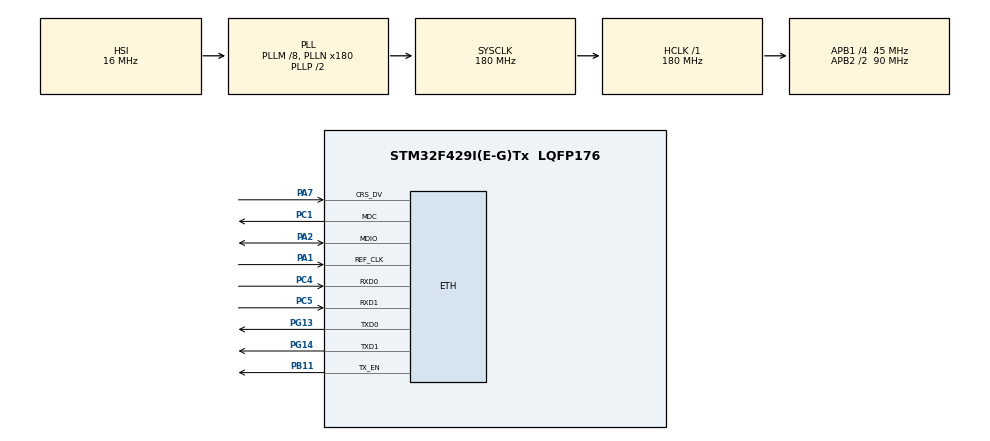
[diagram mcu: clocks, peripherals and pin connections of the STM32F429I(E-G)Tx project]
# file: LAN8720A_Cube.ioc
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ETH.MediaInterface=HAL_ETH_RMII_MODE
LWIP.BSP.number=1
LWIP.GATEWAY_ADDRESS=192.168.001.001
LWIP.IP_ADDRESS=192.168.001.100
LWIP.LWIP_ICMP=1
LWIP.LWIP_UDP=0
LWIP.NETMASK_ADDRESS=255.255.255.000
LWIP.Version=v2.1.2_Cube
LWIP0.BSP.STBoard=false
LWIP0.BSP.api=BSP_COMPONENT_DRIVER
LWIP0.BSP.component=LAN8742
LWIP0.BSP.instance=LAN8742
LWIP0.BSP.name=Driver_PHY
LWIP0.BSP.semaphore=S_LAN8742
LWIP0.BSP.solution=LAN8742
Mcu.Family=STM32F4
Mcu.Name=STM32F429I(E-G)Tx
Mcu.Package=LQFP176
NVIC.PriorityGroup=NVIC_PRIORITYGROUP_4
PA1.Mode=RMII
PA1.Signal=ETH_REF_CLK
PA2.Mode=RMII
PA2.Signal=ETH_MDIO
PA7.Mode=RMII
PA7.Signal=ETH_CRS_DV
PB11.Mode=RMII
PB11.Signal=ETH_TX_EN
PC1.Mode=RMII
PC1.Signal=ETH_MDC
PC4.Mode=RMII
PC4.Signal=ETH_RXD0
PC5.Mode=RMII
PC5.Signal=ETH_RXD1
PG13.Mode=RMII
PG13.Signal=ETH_TXD0
PG14.Mode=RMII
PG14.Signal=ETH_TXD1
ProjectManager.HeapSize=0x200
ProjectManager.StackSize=0x400
ProjectManager.TargetToolchain=MDK-ARM V5.32
RCC.48MHZClocksFreq_Value=90000000
RCC.AHBFreq_Value=180000000
RCC.APB1CLKDivider=RCC_HCLK_DIV4
RCC.APB1Freq_Value=45000000
RCC.APB1TimFreq_Value=90000000
RCC.APB2CLKDivider=RCC_HCLK_DIV2
RCC.APB2Freq_Value=90000000
RCC.APB2TimFreq_Value=180000000
RCC.CortexFreq_Value=180000000
RCC.HCLKFreq_Value=180000000
RCC.HSE_VALUE=25000000
RCC.HSI_VALUE=16000000
RCC.LSE_VALUE=32768
RCC.PLLM=8
RCC.PLLN=180
RCC.SYSCLKFreq_VALUE=180000000
RCC.SYSCLKSource=RCC_SYSCLKSOURCE_PLLCLK
RCC.VCOOutputFreq_Value=360000000
VP_LWIP_VS_Enabled.Mode=Enabled
board=custom

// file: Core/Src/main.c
/* USER CODE BEGIN Header */
/**
  ******************************************************************************
  * @file           : main.c
  * @brief          : Main program body
  ******************************************************************************
  * @attention
  *
  * Copyright (c) 2025 STMicroelectronics.
  * All rights reserved.
  *
  * This software is licensed under terms that can be found in the LICENSE file
  * in the root directory of this software component.
  * If no LICENSE file comes with this software, it is provided AS-IS.
  *
  ******************************************************************************
  */
/* USER CODE END Header */
#include "main.h"
#include "lwip.h"
#include "gpio.h"

/* USER CODE BEGIN Includes */
#include "tcpclient.h"
#include "tcpserver.h"
/* USER CODE END Includes */

void SystemClock_Config(void);

int main(void)
{

  /* MCU Configuration--------------------------------------------------------*/

  /* Reset of all peripherals, Initializes the Flash interface and the Systick. */
  HAL_Init();

  /* Configure the system clock */
  SystemClock_Config();

  /* Initialize all configured peripherals */
  MX_GPIO_Init();
  MX_LWIP_Init();
  /* USER CODE BEGIN 2 */
	TCP_Client_Init();
	TCP_Echo_Init();
  /* USER CODE END 2 */

  /* Infinite loop */
  /* USER CODE BEGIN WHILE */
  while (1)
  {
		MX_LWIP_Process();
    /* USER CODE END WHILE */

  }
}

void SystemClock_Config(void)
{
  RCC_OscInitTypeDef RCC_OscInitStruct = {0};
  RCC_ClkInitTypeDef RCC_ClkInitStruct = {0};

  /** Configure the main internal regulator output voltage
  */
  __HAL_RCC_PWR_CLK_ENABLE();
  __HAL_PWR_VOLTAGESCALING_CONFIG(PWR_REGULATOR_VOLTAGE_SCALE1);

  /** Initializes the RCC Oscillators according to the specified parameters
  * in the RCC_OscInitTypeDef structure.
  */
  RCC_OscInitStruct.OscillatorType = RCC_OSCILLATORTYPE_HSI;
  RCC_OscInitStruct.HSIState = RCC_HSI_ON;
  RCC_OscInitStruct.HSICalibrationValue = RCC_HSICALIBRATION_DEFAULT;
  RCC_OscInitStruct.PLL.PLLState = RCC_PLL_ON;
  RCC_OscInitStruct.PLL.PLLSource = RCC_PLLSOURCE_HSI;
  RCC_OscInitStruct.PLL.PLLM = 8;
  RCC_OscInitStruct.PLL.PLLN = 180;
  RCC_OscInitStruct.PLL.PLLP = RCC_PLLP_DIV2;
  RCC_OscInitStruct.PLL.PLLQ = 4;
  if (HAL_RCC_OscConfig(&RCC_OscInitStruct) != HAL_OK)
  {
    Error_Handler();
  }

  /** Activate the Over-Drive mode
  */
  if (HAL_PWREx_EnableOverDrive() != HAL_OK)
  {
    Error_Handler();
  }

  /** Initializes the CPU, AHB and APB buses clocks
  */
  RCC_ClkInitStruct.ClockType = RCC_CLOCKTYPE_HCLK|RCC_CLOCKTYPE_SYSCLK
                              |RCC_CLOCKTYPE_PCLK1|RCC_CLOCKTYPE_PCLK2;
  RCC_ClkInitStruct.SYSCLKSource = RCC_SYSCLKSOURCE_PLLCLK;
  RCC_ClkInitStruct.AHBCLKDivider = RCC_SYSCLK_DIV1;
  RCC_ClkInitStruct.APB1CLKDivider = RCC_HCLK_DIV4;
  RCC_ClkInitStruct.APB2CLKDivider = RCC_HCLK_DIV2;

  if (HAL_RCC_ClockConfig(&RCC_ClkInitStruct, FLASH_LATENCY_5) != HAL_OK)
  {
    Error_Handler();
  }
}

void Error_Handler(void)
{
  __disable_irq();
  while (1)
  {
  }
}
